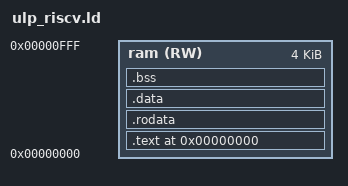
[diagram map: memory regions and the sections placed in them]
       
ENTRY(reset_vector)
MEMORY
{
    ram(RW) : ORIGIN = 0, LENGTH = 4096
}
SECTIONS
{
    . = ORIGIN(ram);
    .text :
    {
        *start.S.obj(.text.vectors)
        *(.text)
        *(.text*)
    } >ram
    .rodata ALIGN(4):
    {
        *(.rodata)
        *(.rodata*)
    } > ram
    .data ALIGN(4):
    {
        *(.data)
        *(.data*)
        *(.sdata)
        *(.sdata*)
    } > ram
    .bss ALIGN(4) :
    {
        *(.bss)
        *(.bss*)
        *(.sbss)
        *(.sbss*)
    } >ram
    __stack_top = ORIGIN(ram) + LENGTH(ram);
}
